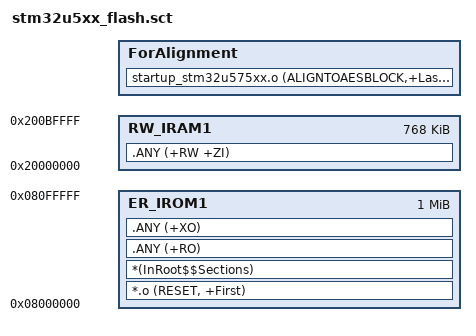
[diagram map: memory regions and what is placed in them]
; *************************************************************
; *** Scatter-Loading Description File generated by uVision ***
; *************************************************************

LR_IROM1 0x08000000 0x00100000 {    ; load region size_region
  ER_IROM1 0x08000000 0x00100000 {  ; load address = execution address
   *.o (RESET, +First)
   *(InRoot$$Sections)
   .ANY (+RO)
   .ANY (+XO)
  }
  RW_IRAM1 0x20000000 0x000C0000  {  ; RW data
   .ANY (+RW +ZI)
  }
}

LR_ROM1(+0) ALIGN(16) {
  ForAlignment +0 {
    startup_stm32u575xx.o (ALIGNTOAESBLOCK,+Last)
  }
}
